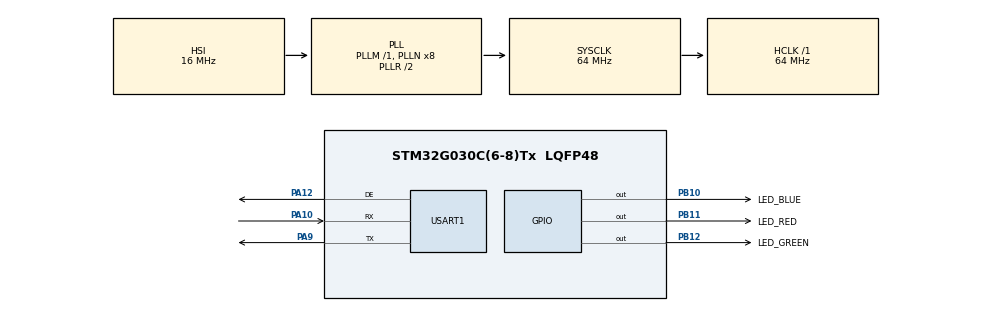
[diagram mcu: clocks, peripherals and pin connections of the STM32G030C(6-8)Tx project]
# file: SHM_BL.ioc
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CRC.CRCLength=CRC_POLYLENGTH_16B
CRC.DefaultInitValueUse=DEFAULT_INIT_VALUE_DISABLE
CRC.DefaultPolynomialUse=DEFAULT_POLYNOMIAL_DISABLE
CRC.GeneratingPolynomial=X12+X5+X0
Mcu.Family=STM32G0
Mcu.Name=STM32G030C(6-8)Tx
Mcu.Package=LQFP48
PA10.Mode=Asynchronous
PA10.Signal=USART1_RX
PA12\ [PA10].Mode=Hardware Flow Control (RS485)
PA12\ [PA10].Signal=USART1_DE
PA9.Mode=Asynchronous
PA9.Signal=USART1_TX
PB10.GPIO_Label=LED_BLUE
PB10.Signal=GPIO_Output
PB11.GPIO_Label=LED_RED
PB11.Signal=GPIO_Output
PB12.GPIO_Label=LED_GREEN
PB12.Signal=GPIO_Output
ProjectManager.HeapSize=0x200
ProjectManager.StackSize=0x400
ProjectManager.TargetToolchain=STM32CubeIDE
RCC.ADCFreq_Value=64000000
RCC.AHBFreq_Value=64000000
RCC.CortexFreq_Value=64000000
RCC.EXTERNAL_CLOCK_VALUE=12288000
RCC.HCLKFreq_Value=64000000
RCC.HSE_VALUE=8000000
RCC.HSI_VALUE=16000000
RCC.LSE_VALUE=32768
RCC.SYSCLKFreq_VALUE=64000000
RCC.SYSCLKSource=RCC_SYSCLKSOURCE_PLLCLK
RCC.VCOOutputFreq_Value=128000000
USART1.VirtualMode-Asynchronous=VM_ASYNC
USART1.VirtualMode-Hardware\ Flow\ Control\ (RS485)=VM_ASYNC
VP_CRC_VS_CRC.Mode=CRC_Activate
board=custom

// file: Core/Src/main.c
/* USER CODE BEGIN Header */
/**
  ******************************************************************************
  * @file           : main.c
  * @brief          : Main program body
  ******************************************************************************
  * @attention
  *
  * <h2><center>&copy; Copyright (c) 2023 STMicroelectronics.
  * All rights reserved.</center></h2>
  *
  * This software component is licensed by ST under BSD 3-Clause license,
  * the "License"; You may not use this file except in compliance with the
  * License. You may obtain a copy of the License at:
  *                        opensource.org/licenses/BSD-3-Clause
  *
  ******************************************************************************
  */
/* USER CODE END Header */
#include "main.h"

/* USER CODE BEGIN Includes */
#include "app_execute.h"
/* USER CODE END Includes */

CRC_HandleTypeDef hcrc;

UART_HandleTypeDef huart1;

void SystemClock_Config(void);
static void MX_GPIO_Init(void);
static void MX_CRC_Init(void);
static void MX_USART1_UART_Init(void);

int main(void)
{

  /* MCU Configuration--------------------------------------------------------*/

  /* Reset of all peripherals, Initializes the Flash interface and the Systick. */
  HAL_Init();

  /* Configure the system clock */
  SystemClock_Config();

  /* Initialize all configured peripherals */
  MX_GPIO_Init();
  MX_CRC_Init();
  MX_USART1_UART_Init();

  /* Infinite loop */
  while (1)
  {
    // todo: my test
	  app_execute();
  }
}

void SystemClock_Config(void)
{
  RCC_OscInitTypeDef RCC_OscInitStruct = {0};
  RCC_ClkInitTypeDef RCC_ClkInitStruct = {0};
  RCC_PeriphCLKInitTypeDef PeriphClkInit = {0};

  /** Configure the main internal regulator output voltage
  */
  HAL_PWREx_ControlVoltageScaling(PWR_REGULATOR_VOLTAGE_SCALE1);
  /** Initializes the RCC Oscillators according to the specified parameters
  * in the RCC_OscInitTypeDef structure.
  */
  RCC_OscInitStruct.OscillatorType = RCC_OSCILLATORTYPE_HSI;
  RCC_OscInitStruct.HSIState = RCC_HSI_ON;
  RCC_OscInitStruct.HSIDiv = RCC_HSI_DIV1;
  RCC_OscInitStruct.HSICalibrationValue = RCC_HSICALIBRATION_DEFAULT;
  RCC_OscInitStruct.PLL.PLLState = RCC_PLL_ON;
  RCC_OscInitStruct.PLL.PLLSource = RCC_PLLSOURCE_HSI;
  RCC_OscInitStruct.PLL.PLLM = RCC_PLLM_DIV1;
  RCC_OscInitStruct.PLL.PLLN = 8;
  RCC_OscInitStruct.PLL.PLLP = RCC_PLLP_DIV2;
  RCC_OscInitStruct.PLL.PLLR = RCC_PLLR_DIV2;
  if (HAL_RCC_OscConfig(&RCC_OscInitStruct) != HAL_OK)
  {
    Error_Handler();
  }
  /** Initializes the CPU, AHB and APB buses clocks
  */
  RCC_ClkInitStruct.ClockType = RCC_CLOCKTYPE_HCLK|RCC_CLOCKTYPE_SYSCLK
                              |RCC_CLOCKTYPE_PCLK1;
  RCC_ClkInitStruct.SYSCLKSource = RCC_SYSCLKSOURCE_PLLCLK;
  RCC_ClkInitStruct.AHBCLKDivider = RCC_SYSCLK_DIV1;
  RCC_ClkInitStruct.APB1CLKDivider = RCC_HCLK_DIV1;

  if (HAL_RCC_ClockConfig(&RCC_ClkInitStruct, FLASH_LATENCY_2) != HAL_OK)
  {
    Error_Handler();
  }
  /** Initializes the peripherals clocks
  */
  PeriphClkInit.PeriphClockSelection = RCC_PERIPHCLK_USART1;
  PeriphClkInit.Usart1ClockSelection = RCC_USART1CLKSOURCE_PCLK1;
  if (HAL_RCCEx_PeriphCLKConfig(&PeriphClkInit) != HAL_OK)
  {
    Error_Handler();
  }
}

static void MX_CRC_Init(void)
{

  hcrc.Instance = CRC;
  hcrc.Init.DefaultPolynomialUse = DEFAULT_POLYNOMIAL_DISABLE;
  hcrc.Init.DefaultInitValueUse = DEFAULT_INIT_VALUE_DISABLE;
  hcrc.Init.GeneratingPolynomial = 4129;
  hcrc.Init.CRCLength = CRC_POLYLENGTH_16B;
  hcrc.Init.InitValue = 0;
  hcrc.Init.InputDataInversionMode = CRC_INPUTDATA_INVERSION_NONE;
  hcrc.Init.OutputDataInversionMode = CRC_OUTPUTDATA_INVERSION_DISABLE;
  hcrc.InputDataFormat = CRC_INPUTDATA_FORMAT_BYTES;
  if (HAL_CRC_Init(&hcrc) != HAL_OK)
  {
    Error_Handler();
  }

}

static void MX_USART1_UART_Init(void)
{

  huart1.Instance = USART1;
  huart1.Init.BaudRate = 115200;
  huart1.Init.WordLength = UART_WORDLENGTH_8B;
  huart1.Init.StopBits = UART_STOPBITS_1;
  huart1.Init.Parity = UART_PARITY_NONE;
  huart1.Init.Mode = UART_MODE_TX_RX;
  huart1.Init.HwFlowCtl = UART_HWCONTROL_NONE;
  huart1.Init.OverSampling = UART_OVERSAMPLING_16;
  huart1.Init.OneBitSampling = UART_ONE_BIT_SAMPLE_DISABLE;
  huart1.Init.ClockPrescaler = UART_PRESCALER_DIV1;
  huart1.AdvancedInit.AdvFeatureInit = UART_ADVFEATURE_NO_INIT;
  if (HAL_RS485Ex_Init(&huart1, UART_DE_POLARITY_HIGH, 0, 0) != HAL_OK)
  {
    Error_Handler();
  }
  if (HAL_UARTEx_SetTxFifoThreshold(&huart1, UART_TXFIFO_THRESHOLD_1_8) != HAL_OK)
  {
    Error_Handler();
  }
  if (HAL_UARTEx_SetRxFifoThreshold(&huart1, UART_RXFIFO_THRESHOLD_1_8) != HAL_OK)
  {
    Error_Handler();
  }
  if (HAL_UARTEx_DisableFifoMode(&huart1) != HAL_OK)
  {
    Error_Handler();
  }

}

static void MX_GPIO_Init(void)
{
  GPIO_InitTypeDef GPIO_InitStruct = {0};

  /* GPIO Ports Clock Enable */
  __HAL_RCC_GPIOB_CLK_ENABLE();
  __HAL_RCC_GPIOA_CLK_ENABLE();

  /*Configure GPIO pin Output Level */
  HAL_GPIO_WritePin(GPIOB, LED_BLUE_Pin|LED_RED_Pin|LED_GREEN_Pin, GPIO_PIN_RESET);

  /*Configure GPIO pins : LED_BLUE_Pin LED_RED_Pin LED_GREEN_Pin */
  GPIO_InitStruct.Pin = LED_BLUE_Pin|LED_RED_Pin|LED_GREEN_Pin;
  GPIO_InitStruct.Mode = GPIO_MODE_OUTPUT_PP;
  GPIO_InitStruct.Pull = GPIO_NOPULL;
  GPIO_InitStruct.Speed = GPIO_SPEED_FREQ_LOW;
  HAL_GPIO_Init(GPIOB, &GPIO_InitStruct);

}

void Error_Handler(void)
{
  __disable_irq();
  while (1)
  {
  }
}

/************************ (C) COPYRIGHT STMicroelectronics *****END OF FILE****/
